# PCIE1_CORE_VMAP_MMRS register map
Vendor: Texas Instruments
Peripheral module from a debugger description file (folder J7_AHP).
Registers are 32-bit, read-write, reset 0x100FFF unless marked. A register's access mark holds for its fields unless they carry their own. Offsets are as the file gives them; lines under a group give offsets from that group; [hi:lo] are bit positions; {n}, {i} and the like mark numbered series; 'fields as' and 'values as' point back to an identical list; <NAME> marks a mode.

## PCIE1_CORE_VMAP_MMRS
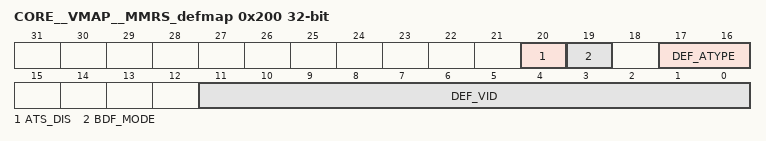
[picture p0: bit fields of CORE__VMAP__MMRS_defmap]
0x200 CORE__VMAP__MMRS_defmap
  [20] ATS_DIS — ATS mode. 1-ATS is disabled, 0-ATS is enabled
  [19] BDF_MODE — Bus default mode. 0-Use default bus numbers, 1-Use offset bus numbers
  [17:16] DEF_ATYPE — Default address type attribute. 0-Physical Address, 1-Intermediate Address, 2-Virtual Address, 3-Translated Address
  [11:0] DEF_VID — Default match ID
0x400 CORE__VMAP__MMRS_ob_virtid_match reset 0x0
  [11:5] VAL — Outbound virtid[11:5] match value. When outbound VBUSM slave interface virtid[11:5] matches the value in this register and the ASEL value is non-zero, the PCIe controller address translation unit (ATU) is bypassed. The PCIe TLP descriptor values are taken from the ext_desc registers.
